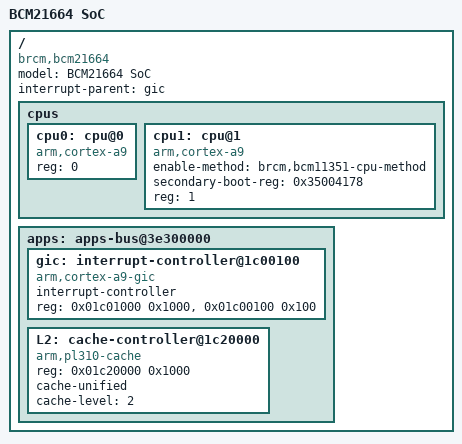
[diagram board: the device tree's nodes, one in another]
// SPDX-License-Identifier: BSD-3-Clause
/*
 * Device tree for the BCM21664 SoC.
 *
 * Copyright (C) 2014 Broadcom Corporation
 */

#include "bcm216xx.dtsi"

/ {
	model = "BCM21664 SoC";
	compatible = "brcm,bcm21664";
	interrupt-parent = <&gic>;

	cpus {
		#address-cells = <1>;
		#size-cells = <0>;

		cpu0: cpu@0 {
			device_type = "cpu";
			compatible = "arm,cortex-a9";
			reg = <0>;
		};

		cpu1: cpu@1 {
			device_type = "cpu";
			compatible = "arm,cortex-a9";
			enable-method = "brcm,bcm11351-cpu-method";
			secondary-boot-reg = <0x35004178>;
			reg = <1>;
		};
	};

	apps: apps-bus@3e300000 {
		gic: interrupt-controller@1c00100 {
			compatible = "arm,cortex-a9-gic";
			#interrupt-cells = <3>;
			#address-cells = <0>;
			interrupt-controller;
			reg = <0x01c01000 0x1000>,
			      <0x01c00100 0x100>;
		};

		L2: cache-controller@1c20000 {
			compatible = "arm,pl310-cache";
			reg = <0x01c20000 0x1000>;
			cache-unified;
			cache-level = <2>;
		};
	};
};
